# STC32G144K246 register map
Vendor: STC; File version: 2.0
Registers are 8-bit, read-write, no defined reset value unless marked. A register's access mark holds for its fields unless they carry their own. Offsets are from the block's base; [hi:lo] are bit positions.

## Timer2_4 — Timer2/3/4：控制、计数和预分频
Base 0x007EFEA2
0x00 TM2PS — 定时器2时钟预分频寄存器
  [7:0] TM2PS — 尚未自动匹配到此字段的独立说明；请查看下方章节说明。
0x01 TM3PS — 定时器3时钟预分频寄存器
  [7:0] TM3PS — 尚未自动匹配到此字段的独立说明；请查看下方章节说明。
0x02 TM4PS — 定时器4时钟预分频寄存器
  [7:0] TM4PS — 尚未自动匹配到此字段的独立说明；请查看下方章节说明。
0xF810230 T4H ro — 定时器4高字节
  [7:0] TMR4 — 尚未自动匹配到此字段的独立说明；请查看下方章节说明。
0xF810231 T4L ro — 定时器4低字节
  [7:0] TMR4 — 尚未自动匹配到此字段的独立说明；请查看下方章节说明。
0xF810232 T3H ro — 定时器3高字节
  [7:0] TMR3 — 尚未自动匹配到此字段的独立说明；请查看下方章节说明。
0xF810233 T3L ro — 定时器3低字节
  [7:0] TMR3 — 尚未自动匹配到此字段的独立说明；请查看下方章节说明。
0xF810234 T2H ro — 定时器2高字节
  [7:0] TMR2 — 尚未自动匹配到此字段的独立说明；请查看下方章节说明。
0xF810235 T2L ro — 定时器2低字节
  [7:0] TMR2 — 尚未自动匹配到此字段的独立说明；请查看下方章节说明。
0xF81023B T3T4M — 定时器4/3控制寄存器

## Timer5_6 — Timer5/6：共用控制、独立计数和预分频
Base 0x007EFBB0
0x00 TM5PS — 定时器5预分频寄存器
  [7:0] TM5PS — 尚未自动匹配到此字段的独立说明；请查看下方章节说明。
0x01 TM6PS — 定时器6预分频寄存器
  [7:0] TM6PS — 尚未自动匹配到此字段的独立说明；请查看下方章节说明。
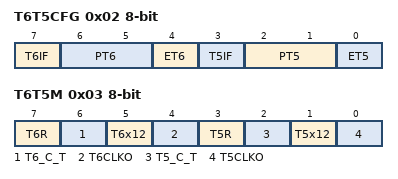
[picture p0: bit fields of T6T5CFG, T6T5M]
0x02 T6T5CFG — 定时器6/5配置寄存器
  [7] T6IF — 定时器6溢出中断标志。需软件写0清零。
  [6:5] PT6 — 定时器6中断优先级控制位
    0=定时器6 中断优先级为0 级（最低级）; 1=定时器6 中断优先级为1 级（较低级）; 2=定时器6 中断优先级为2 级（较高级）; 3=定时器6 中断优先级为3 级（最高级）
  [4] ET6 — 定时/计数器T6 的溢出中断允许位。
    0=禁止T6 中断; 1=允许T6 中断
  [3] T5IF — 定时器5溢出中断标志。需软件写0清零。
  [2:1] PT5 — 定时器5中断优先级控制位
    0=定时器5 中断优先级为0 级（最低级）; 1=定时器5 中断优先级为1 级（较低级）; 2=定时器5 中断优先级为2 级（较高级）; 3=定时器5 中断优先级为3 级（最高级）
  [0] ET5 — 定时/计数器T5 的溢出中断允许位。
    0=禁止T5 中断; 1=允许T5 中断
0x03 T6T5M — 定时器6/5控制寄存器
  [7] T6R — 定时器6的运行控制位
    0=定时器6 停止计数; 1=定时器6 开始计数
  [6] T6_C_T — 控制定时器6用作定时器或计数器，清0则用作定时器（对内部系统时钟进行计数），置1用作
  [5] T6x12 — 定时器6速度控制位
    0=12T 模式，即CPU 时钟12 分频（FOSC/12）; 1=1T 模式，即CPU 时钟不分频分频（FOSC/1）
  [4] T6CLKO — 定时器6时钟输出控制
    0=关闭时钟输出; 1=使能T6CLKO/P2.3 口的是定时器6 时钟输出功能
  [3] T5R — 定时器5的运行控制位
    0=定时器5 停止计数; 1=定时器5 开始计数
  [2] T5_C_T — 控制定时器5用作定时器或计数器，清0则用作定时器（对内部系统时钟进行计数），置1用作
  [1] T5x12 — 定时器5速度控制位
    0=12T 模式，即CPU 时钟12 分频（FOSC/12）; 1=1T 模式，即CPU 时钟不分频分频（FOSC/1）
  [0] T5CLKO — 定时器5时钟输出控制
    0=关闭时钟输出; 1=使能T5CLKO/P2.1 口的是定时器5 时钟输出功能
0x04 T6H ro — 定时器6高字节
  [7:0] TMR6 — 尚未自动匹配到此字段的独立说明；请查看下方章节说明。
0x05 T6L ro — 定时器6低字节
  [7:0] TMR6 — 尚未自动匹配到此字段的独立说明；请查看下方章节说明。
0x06 T5H ro — 定时器5高字节
  [7:0] TMR5 — 尚未自动匹配到此字段的独立说明；请查看下方章节说明。
0x07 T5L ro — 定时器5低字节
  [7:0] TMR5 — 尚未自动匹配到此字段的独立说明；请查看下方章节说明。

## Timer7_8 — Timer7/8：共用控制、独立计数和预分频
Base 0x007EFBB8
0x00 TM7PS — 定时器7预分频寄存器
  [7:0] TM7PS — 尚未自动匹配到此字段的独立说明；请查看下方章节说明。
0x01 TM8PS — 定时器8预分频寄存器
  [7:0] TM8PS — 尚未自动匹配到此字段的独立说明；请查看下方章节说明。
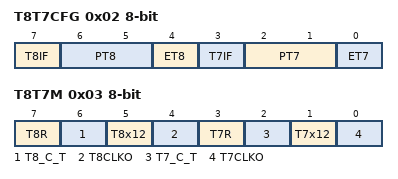
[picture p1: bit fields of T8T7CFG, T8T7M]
0x02 T8T7CFG — 定时器8/7配置寄存器
  [7] T8IF — 定时器8溢出中断标志。需软件写0清零。
  [6:5] PT8 — 定时器8中断优先级控制位
    0=定时器8 中断优先级为0 级（最低级）; 1=定时器8 中断优先级为1 级（较低级）; 2=定时器8 中断优先级为2 级（较高级）; 3=定时器8 中断优先级为3 级（最高级）
  [4] ET8 — 定时/计数器T8 的溢出中断允许位。
    0=禁止T8 中断; 1=允许T8 中断
  [3] T7IF — 定时器7溢出中断标志。需软件写0清零。
  [2:1] PT7 — 定时器7中断优先级控制位
    0=定时器7 中断优先级为0 级（最低级）; 1=定时器7 中断优先级为1 级（较低级）; 2=定时器7 中断优先级为2 级（较高级）; 3=定时器7 中断优先级为3 级（最高级）
  [0] ET7 — 定时/计数器T7 的溢出中断允许位。
    0=禁止T7 中断; 1=允许T7 中断
0x03 T8T7M — 定时器8/7控制寄存器
  [7] T8R — 定时器8的运行控制位
    0=定时器8 停止计数; 1=定时器8 开始计数
  [6] T8_C_T — 控制定时器8用作定时器或计数器，清0则用作定时器（对内部系统时钟进行计数），置1用作
  [5] T8x12 — 定时器8速度控制位
    0=12T 模式，即CPU 时钟12 分频（FOSC/12）; 1=1T 模式，即CPU 时钟不分频分频（FOSC/1）
  [4] T8CLKO — 定时器8时钟输出控制
    0=关闭时钟输出; 1=使能T8CLKO/P2.7 口的是定时器8 时钟输出功能
  [3] T7R — 定时器7的运行控制位
    0=定时器7 停止计数; 1=定时器7 开始计数
  [2] T7_C_T — 控制定时器7用作定时器或计数器，清0则用作定时器（对内部系统时钟进行计数），置1用作
  [1] T7x12 — 定时器7速度控制位
    0=12T 模式，即CPU 时钟12 分频（FOSC/12）; 1=1T 模式，即CPU 时钟不分频分频（FOSC/1）
  [0] T7CLKO — 定时器7时钟输出控制
    0=关闭时钟输出; 1=使能T7CLKO/P2.5 口的是定时器7 时钟输出功能
0x04 T8H ro — 定时器8高字节
  [7:0] TMR8 — 尚未自动匹配到此字段的独立说明；请查看下方章节说明。
0x05 T8L ro — 定时器8低字节
  [7:0] TMR8 — 尚未自动匹配到此字段的独立说明；请查看下方章节说明。
0x06 T7H ro — 定时器7高字节
  [7:0] TMR7 — 尚未自动匹配到此字段的独立说明；请查看下方章节说明。
0x07 T7L ro — 定时器7低字节
  [7:0] TMR7 — 尚未自动匹配到此字段的独立说明；请查看下方章节说明。

## Timer9_10 — Timer9/10：共用控制、独立计数和预分频
Base 0x007EFBC0
0x00 TM9PS — 定时器9预分频寄存器
  [7:0] TM9PS — 尚未自动匹配到此字段的独立说明；请查看下方章节说明。
0x01 TM10PS — 定时器10预分频寄存器
  [7:0] TM10PS — 尚未自动匹配到此字段的独立说明；请查看下方章节说明。
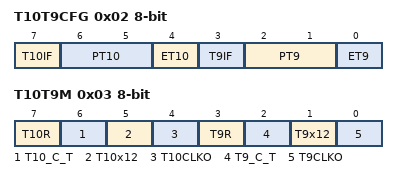
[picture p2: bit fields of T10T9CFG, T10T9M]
0x02 T10T9CFG — 定时器10/9配置寄存器
  [7] T10IF — 定时器10溢出中断标志。需软件写0清零。
  [6:5] PT10 — 定时器10中断优先级控制位
    0=定时器10 中断优先级为0 级（最低级）; 1=定时器10 中断优先级为1 级（较低级）; 2=定时器10 中断优先级为2 级（较高级）; 3=定时器10 中断优先级为3 级（最高级）
  [4] ET10 — 定时/计数器T10 的溢出中断允许位。
    0=禁止T10 中断; 1=允许T10 中断
  [3] T9IF — 定时器9溢出中断标志。需软件写0清零。
  [2:1] PT9 — 定时器9 中断优先级控制位
    0=定时器9 中断优先级为0 级（最低级）; 1=定时器9 中断优先级为1 级（较低级）; 2=定时器9 中断优先级为2 级（较高级）; 3=定时器9 中断优先级为3 级（最高级）
  [0] ET9 — 定时/计数器T9 的溢出中断允许位。
    0=禁止T9 中断; 1=允许T9 中断
0x03 T10T9M — 定时器10/9控制寄存器
  [7] T10R — 定时器10的运行控制位
    0=定时器10 停止计数; 1=定时器10 开始计数
  [6] T10_C_T — 控制定时器10用作定时器或计数器，清0则用作定时器（对内部系统时钟进行计数），置1用
  [5] T10x12 — 定时器10速度控制位
    0=12T 模式，即CPU 时钟12 分频（FOSC/12）; 1=1T 模式，即CPU 时钟不分频分频（FOSC/1）
  [4] T10CLKO — 定时器10时钟输出控制
    0=关闭时钟输出; 1=使能T10CLKO/P6.1 口的是定时器10 时钟输出功能
  [3] T9R — 定时器9的运行控制位
    0=定时器9 停止计数; 1=定时器9 开始计数
  [2] T9_C_T — 控制定时器9用作定时器或计数器，清0则用作定时器（对内部系统时钟进行计数），置1用作
  [1] T9x12 — 定时器9速度控制位
    0=12T 模式，即CPU 时钟12 分频（FOSC/12）; 1=1T 模式，即CPU 时钟不分频分频（FOSC/1）
  [0] T9CLKO — 定时器9时钟输出控制
    0=关闭时钟输出; 1=使能T9CLKO/P7.1 口的是定时器9 时钟输出功能
0x04 T10H ro — 定时器10高字节
  [7:0] TMR10 — 尚未自动匹配到此字段的独立说明；请查看下方章节说明。
0x05 T10L ro — 定时器10低字节
  [7:0] TMR10 — 尚未自动匹配到此字段的独立说明；请查看下方章节说明。
0x06 T9H ro — 定时器9高字节
  [7:0] TMR9 — 尚未自动匹配到此字段的独立说明；请查看下方章节说明。
0x07 T9L ro — 定时器9低字节
  [7:0] TMR9 — 尚未自动匹配到此字段的独立说明；请查看下方章节说明。
